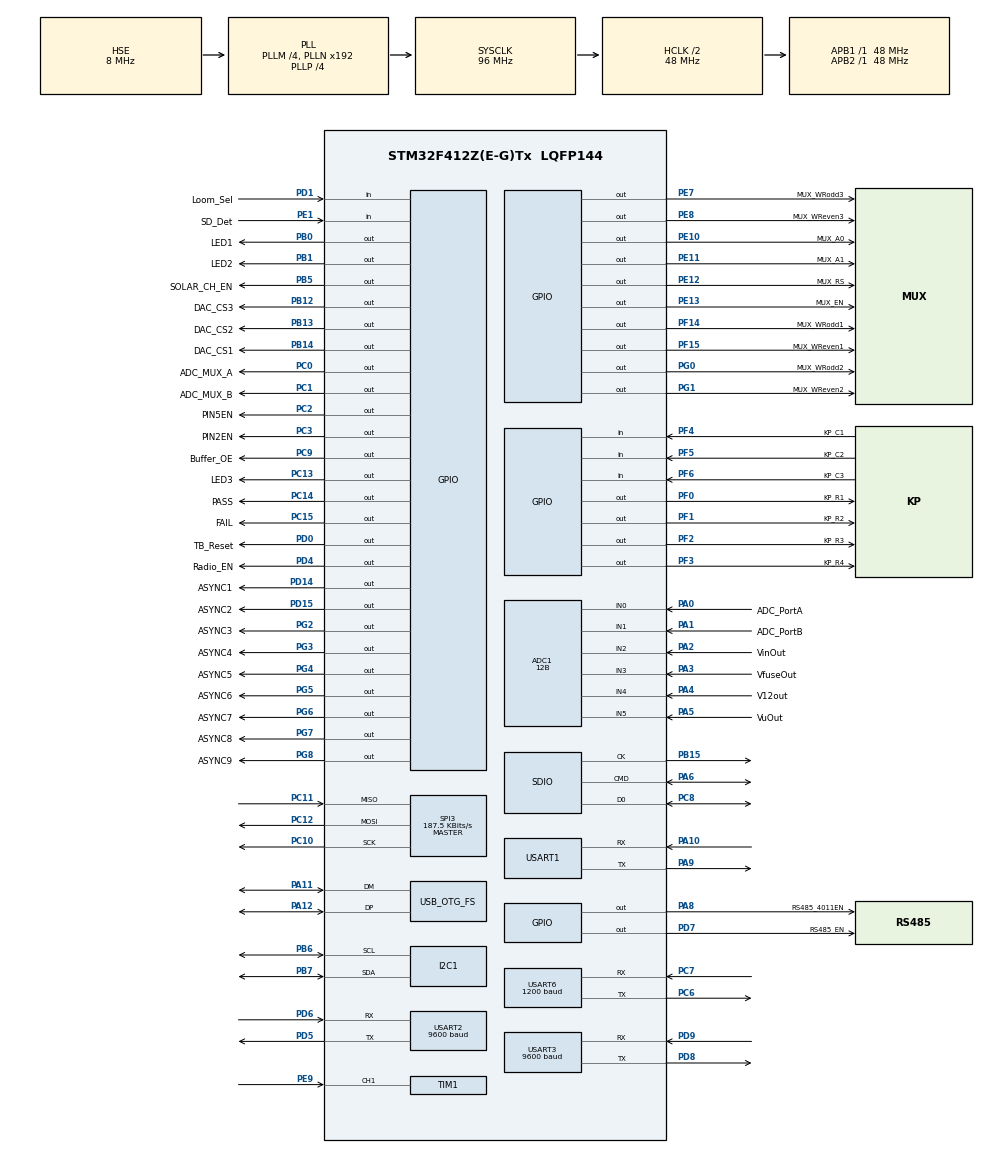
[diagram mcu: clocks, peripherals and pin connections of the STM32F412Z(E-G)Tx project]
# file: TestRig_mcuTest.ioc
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ADC1.Channel-0\#ChannelRegularConversion=ADC_CHANNEL_0
ADC1.ClockPrescaler=ADC_CLOCK_SYNC_PCLK_DIV2
ADC1.ContinuousConvMode=ENABLE
ADC1.DMAContinuousRequestsForConfigFile-ADC_Settings=LIMITED
ADC1.EOCSelection=ADC_EOC_SINGLE_CONV
ADC1.InjNumberOfConversion=0
ADC1.NbrOfConversion=1
ADC1.NbrOfConversionFlag=1
ADC1.Rank-0\#ChannelRegularConversion=1
ADC1.Resolution=ADC_RESOLUTION_12B
ADC1.SamplingTime-0\#ChannelRegularConversion=ADC_SAMPLETIME_3CYCLES
ADC1.ScanConvMode=ENABLE
ADC1.master=1
FATFS._FS_RPATH=1
FATFS._USE_CHMOD=0
FATFS._USE_FIND=1
FATFS._USE_LFN=1
Mcu.Family=STM32F4
Mcu.Name=STM32F412Z(E-G)Tx
Mcu.Package=LQFP144
NVIC.OTG_FS_IRQn=true\:0\:0\:false\:false\:true\:false\:true
NVIC.PriorityGroup=NVIC_PRIORITYGROUP_4
NVIC.TIM1_TRG_COM_TIM11_IRQn=true\:0\:0\:false\:false\:true\:true\:true
NVIC.TIM1_UP_TIM10_IRQn=true\:0\:0\:false\:false\:true\:true\:true
NVIC.TIM6_IRQn=true\:0\:0\:false\:false\:true\:true\:true
NVIC.TIM7_IRQn=true\:0\:0\:false\:false\:true\:true\:true
NVIC.TIM8_TRG_COM_TIM14_IRQn=true\:0\:0\:false\:false\:true\:true\:true
NVIC.USART2_IRQn=true\:0\:0\:false\:false\:true\:true\:true
NVIC.USART3_IRQn=true\:0\:0\:false\:false\:true\:true\:true
NVIC.USART6_IRQn=true\:0\:0\:false\:false\:true\:true\:true
PA0.GPIO_Label=ADC_PortA
PA0.Signal=ADCx_IN0
PA1.GPIO_Label=ADC_PortB
PA1.Signal=ADCx_IN1
PA10.Mode=Asynchronous
PA10.Signal=USART1_RX
PA11.Mode=Device_Only
PA11.Signal=USB_OTG_FS_DM
PA12.Mode=Device_Only
PA12.Signal=USB_OTG_FS_DP
PA13.Mode=Trace_Asynchronous_SW
PA13.Signal=SYS_JTMS-SWDIO
PA14.Mode=Trace_Asynchronous_SW
PA14.Signal=SYS_JTCK-SWCLK
PA2.GPIO_Label=VinOut
PA2.Signal=ADCx_IN2
PA3.GPIO_Label=VfuseOut
PA3.Signal=ADCx_IN3
PA4.GPIO_Label=V12out
PA4.Signal=ADCx_IN4
PA5.GPIO_Label=VuOut
PA5.Signal=ADCx_IN5
PA6.Mode=SD_1_bit
PA6.Signal=SDIO_CMD
PA8.GPIO_Label=RS485_4011EN
PA8.Signal=GPIO_Output
PA9.Mode=Asynchronous
PA9.Signal=USART1_TX
PB0.GPIO_Label=LED1
PB0.Signal=GPIO_Output
PB1.GPIO_Label=LED2
PB1.GPIO_Speed=GPIO_SPEED_FREQ_HIGH
PB1.Signal=GPIO_Output
PB12.GPIO_Label=DAC_CS3
PB12.Signal=GPIO_Output
PB13.GPIO_Label=DAC_CS2
PB13.Signal=GPIO_Output
PB14.GPIO_Label=DAC_CS1
PB14.Signal=GPIO_Output
PB15.Mode=SD_1_bit
PB15.Signal=SDIO_CK
PB3.Mode=Trace_Asynchronous_SW
PB3.Signal=SYS_JTDO-SWO
PB5.GPIO_Label=SOLAR_CH_EN
PB5.Signal=GPIO_Output
PB6.Mode=I2C
PB6.Signal=I2C1_SCL
PB7.Mode=I2C
PB7.Signal=I2C1_SDA
PC0.GPIO_Label=ADC_MUX_A
PC0.Signal=GPIO_Output
PC1.GPIO_Label=ADC_MUX_B
PC1.Signal=GPIO_Output
PC10.Mode=Full_Duplex_Master
PC10.Signal=SPI3_SCK
PC11.Mode=Full_Duplex_Master
PC11.Signal=SPI3_MISO
PC12.Mode=Full_Duplex_Master
PC12.Signal=SPI3_MOSI
PC13.GPIO_Label=LED3
PC13.Signal=GPIO_Output
PC14-OSC32_IN.GPIO_Label=PASS
PC14-OSC32_IN.Signal=GPIO_Output
PC15-OSC32_OUT.GPIO_Label=FAIL
PC15-OSC32_OUT.Signal=GPIO_Output
PC2.GPIO_Label=PIN5EN
PC2.Signal=GPIO_Output
PC3.GPIO_Label=PIN2EN
PC3.Signal=GPIO_Output
PC6.Mode=Asynchronous
PC6.Signal=USART6_TX
PC7.Mode=Asynchronous
PC7.Signal=USART6_RX
PC8.Mode=SD_1_bit
PC8.Signal=SDIO_D0
PC9.GPIO_Label=Buffer_OE
PC9.Signal=GPIO_Output
PD0.GPIO_Label=TB_Reset
PD0.GPIO_PuPd=GPIO_NOPULL
PD0.Signal=GPIO_Output
PD1.GPIO_Label=Loom_Sel
PD1.GPIO_PuPd=GPIO_PULLUP
PD1.Signal=GPIO_Input
PD14.GPIO_Label=ASYNC1
PD14.GPIO_Speed=GPIO_SPEED_FREQ_VERY_HIGH
PD14.Signal=GPIO_Output
PD15.GPIO_Label=ASYNC2
PD15.GPIO_Speed=GPIO_SPEED_FREQ_VERY_HIGH
PD15.Signal=GPIO_Output
PD4.GPIO_Label=Radio_EN
PD4.Signal=GPIO_Output
PD5.Mode=Asynchronous
PD5.Signal=USART2_TX
PD6.Mode=Asynchronous
PD6.Signal=USART2_RX
PD7.GPIO_Label=RS485_EN
PD7.Signal=GPIO_Output
PD8.Mode=Asynchronous
PD8.Signal=USART3_TX
PD9.Mode=Asynchronous
PD9.Signal=USART3_RX
PE1.GPIO_Label=SD_Det
PE1.Signal=GPIO_Input
PE10.GPIO_Label=MUX_A0
PE10.Signal=GPIO_Output
PE11.GPIO_Label=MUX_A1
PE11.Signal=GPIO_Output
PE12.GPIO_Label=MUX_RS
PE12.PinState=GPIO_PIN_SET
PE12.Signal=GPIO_Output
PE13.GPIO_Label=MUX_EN
PE13.Signal=GPIO_Output
PE7.GPIO_Label=MUX_WRodd3
PE7.PinState=GPIO_PIN_SET
PE7.Signal=GPIO_Output
PE8.GPIO_Label=MUX_WReven3
PE8.PinState=GPIO_PIN_SET
PE8.Signal=GPIO_Output
PE9.Signal=S_TIM1_CH1
PF0.GPIO_Label=KP_R1
PF0.Signal=GPIO_Output
PF1.GPIO_Label=KP_R2
PF1.Signal=GPIO_Output
PF14.GPIO_Label=MUX_WRodd1
PF14.GPIO_PuPd=GPIO_PULLUP
PF14.PinState=GPIO_PIN_SET
PF14.Signal=GPIO_Output
PF15.GPIO_Label=MUX_WReven1
PF15.GPIO_PuPd=GPIO_PULLUP
PF15.PinState=GPIO_PIN_SET
PF15.Signal=GPIO_Output
PF2.GPIO_Label=KP_R3
PF2.Signal=GPIO_Output
PF3.GPIO_Label=KP_R4
PF3.Signal=GPIO_Output
PF4.GPIO_Label=KP_C1
PF4.GPIO_PuPd=GPIO_PULLUP
PF4.Signal=GPIO_Input
PF5.GPIO_Label=KP_C2
PF5.GPIO_PuPd=GPIO_PULLUP
PF5.Signal=GPIO_Input
PF6.GPIO_Label=KP_C3
PF6.GPIO_PuPd=GPIO_PULLUP
PF6.Signal=GPIO_Input
PG0.GPIO_Label=MUX_WRodd2
PG0.PinState=GPIO_PIN_SET
PG0.Signal=GPIO_Output
PG1.GPIO_Label=MUX_WReven2
PG1.PinState=GPIO_PIN_SET
PG1.Signal=GPIO_Output
PG2.GPIO_Label=ASYNC3
PG2.GPIO_Speed=GPIO_SPEED_FREQ_VERY_HIGH
PG2.PinState=GPIO_PIN_RESET
PG2.Signal=GPIO_Output
PG3.GPIO_Label=ASYNC4
PG3.GPIO_Speed=GPIO_SPEED_FREQ_VERY_HIGH
PG3.Signal=GPIO_Output
PG4.GPIO_Label=ASYNC5
PG4.Signal=GPIO_Output
PG5.GPIO_Label=ASYNC6
PG5.Signal=GPIO_Output
PG6.GPIO_Label=ASYNC7
PG6.Signal=GPIO_Output
PG7.GPIO_Label=ASYNC8
PG7.Signal=GPIO_Output
PG8.GPIO_Label=ASYNC9
PG8.Signal=GPIO_Output
PH0\ -\ OSC_IN.Mode=HSE-External-Oscillator
PH0\ -\ OSC_IN.Signal=RCC_OSC_IN
PH1\ -\ OSC_OUT.Mode=HSE-External-Oscillator
PH1\ -\ OSC_OUT.Signal=RCC_OSC_OUT
ProjectManager.HeapSize=0x200
ProjectManager.StackSize=0x400
ProjectManager.TargetToolchain=STM32CubeIDE
RCC.AHBCLKDivider=RCC_SYSCLK_DIV2
RCC.AHBFreq_Value=48000000
RCC.APB1Freq_Value=48000000
RCC.APB1TimFreq_Value=48000000
RCC.APB2Freq_Value=48000000
RCC.APB2TimFreq_Value=48000000
RCC.CortexFreq_Value=48000000
RCC.HCLKFreq_Value=48000000
RCC.HSE_VALUE=8000000
RCC.PLLM=4
RCC.PLLP=RCC_PLLP_DIV4
RCC.PLLQ=8
RCC.PLLSourceVirtual=RCC_PLLSOURCE_HSE
RCC.SYSCLKFreq_VALUE=96000000
RCC.SYSCLKSource=RCC_SYSCLKSOURCE_PLLCLK
RCC.USBFreq_Value=48000000
RCC.VCOOutputFreq_Value=384000000
SDIO.ClockDiv=2
SDIO.HardwareFlowControl=SDIO_HARDWARE_FLOW_CONTROL_ENABLE
SH.ADCx_IN0.0=ADC1_IN0,IN0
SH.ADCx_IN1.0=ADC1_IN1,IN1
SH.ADCx_IN2.0=ADC1_IN2,IN2
SH.ADCx_IN3.0=ADC1_IN3,IN3
SH.ADCx_IN4.0=ADC1_IN4,IN4
SH.ADCx_IN5.0=ADC1_IN5,IN5
SH.S_TIM1_CH1.0=TIM1_CH1,Input_Capture1_from_TI1
SPI3.BaudRatePrescaler=SPI_BAUDRATEPRESCALER_256
SPI3.CalculateBaudRate=187.5 KBits/s
SPI3.DataSize=SPI_DATASIZE_8BIT
SPI3.Direction=SPI_DIRECTION_2LINES
SPI3.Mode=SPI_MODE_MASTER
SPI3.VirtualType=VM_MASTER
TIM1.Channel-Input_Capture1_from_TI1=TIM_CHANNEL_1
TIM10.AutoReloadPreload=TIM_AUTORELOAD_PRELOAD_ENABLE
TIM10.Period=99
TIM10.Prescaler=239
TIM11.AutoReloadPreload=TIM_AUTORELOAD_PRELOAD_ENABLE
TIM11.Period=47
TIM11.Prescaler=999
TIM13.AutoReloadPreload=TIM_AUTORELOAD_PRELOAD_ENABLE
TIM13.Period=1
TIM13.Prescaler=23
TIM14.AutoReloadPreload=TIM_AUTORELOAD_PRELOAD_ENABLE
TIM14.Period=99
TIM14.Prescaler=239
TIM6.AutoReloadPreload=TIM_AUTORELOAD_PRELOAD_ENABLE
TIM6.Period=479
TIM6.Prescaler=999
TIM7.Period=47
TIM7.Prescaler=999
USART1.VirtualMode=VM_ASYNC
USART2.BaudRate=9600
USART2.VirtualMode=VM_ASYNC
USART3.BaudRate=9600
USART3.VirtualMode=VM_ASYNC
USART6.BaudRate=1200
USART6.Parity=PARITY_EVEN
USART6.VirtualMode=VM_ASYNC
USB_DEVICE.CLASS_NAME_FS=CDC
USB_DEVICE.MANUFACTURER_STRING=MAIT INDUSTRIES
USB_DEVICE.PRODUCT_STRING_CDC_FS=TESTRIG
USB_DEVICE.VirtualMode=Cdc
USB_DEVICE.VirtualModeFS=Cdc_FS
USB_OTG_FS.VirtualMode=Device_Only
VP_FATFS_VS_SDIO.Mode=SDIO
VP_RNG_VS_RNG.Mode=RNG_Activate
VP_TIM10_VS_ClockSourceINT.Mode=Enable_Timer
VP_TIM11_VS_ClockSourceINT.Mode=Enable_Timer
VP_TIM13_VS_ClockSourceINT.Mode=Enable_Timer
VP_TIM14_VS_ClockSourceINT.Mode=Enable_Timer
VP_TIM6_VS_ClockSourceINT.Mode=Enable_Timer
VP_TIM7_VS_ClockSourceINT.Mode=Enable_Timer
VP_USB_DEVICE_VS_USB_DEVICE_CDC_FS.Mode=CDC_FS
board=custom

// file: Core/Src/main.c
/* USER CODE BEGIN Header */
/**
 ******************************************************************************
 * @file           : main.c
 * @brief          : Main program body
 ******************************************************************************
 * @attention
 *
 * <h2><center>&copy; Copyright (c) 2021 STMicroelectronics.
 * All rights reserved.</center></h2>
 *
 * This software component is licensed by ST under BSD 3-Clause license,
 * the "License"; You may not use this file except in compliance with the
 * License. You may obtain a copy of the License at:
 *                        opensource.org/licenses/BSD-3-Clause
 *
 ******************************************************************************
 */
/* USER CODE END Header */
#include "main.h"
#include "fatfs.h"
#include "usb_device.h"

/* USER CODE BEGIN Includes */
#include "ADC_Variables.h"
#include "ADC.h"
#include "Board_Config.h"
#include "Calibration.h"
#include "DAC_Variables.h"
#include "EEPROM.h"
#include "File_Handling.h"
#include "Global_Variables.h"
#include "Init.h"
#include "LCD.h"
#include "Programming.h"
#include "ScanLoom.h"
#include "SDcard.h"
#include "SetVsMeasured.h"
#include "StateMachine.h"
#include "Test.h"
#include "UART_Routine.h"
#include "usbd_cdc_if.h"
/* USER CODE END Includes */

/* USER CODE BEGIN PTD */
extern void reset_ALL_DAC(void);
extern void Async_Init(void);
extern void delay_us(int);
/* USER CODE END PTD */

ADC_HandleTypeDef hadc1;

I2C_HandleTypeDef hi2c1;

RNG_HandleTypeDef hrng;

SD_HandleTypeDef hsd;

SPI_HandleTypeDef hspi3;

TIM_HandleTypeDef htim1;
TIM_HandleTypeDef htim6;
TIM_HandleTypeDef htim7;
TIM_HandleTypeDef htim10;
TIM_HandleTypeDef htim11;
TIM_HandleTypeDef htim13;
TIM_HandleTypeDef htim14;

UART_HandleTypeDef huart1;
UART_HandleTypeDef huart2;
UART_HandleTypeDef huart3;
UART_HandleTypeDef huart6;

void SystemClock_Config(void);
static void MX_GPIO_Init(void);
static void MX_ADC1_Init(void);
static void MX_I2C1_Init(void);
static void MX_SDIO_SD_Init(void);
static void MX_SPI3_Init(void);
static void MX_TIM6_Init(void);
static void MX_TIM7_Init(void);
static void MX_TIM13_Init(void);
static void MX_TIM14_Init(void);
static void MX_USART2_UART_Init(void);
static void MX_USART3_UART_Init(void);
static void MX_USART6_UART_Init(void);
static void MX_TIM10_Init(void);
static void MX_USART1_UART_Init(void);
static void MX_TIM11_Init(void);
static void MX_RNG_Init(void);
static void MX_TIM1_Init(void);
/* USER CODE BEGIN PFP */
uint32 read_serial(void);
void read_correctionFactors(void);
void write_correctionFactors(void);
void LCD_init(void);
/* USER CODE END PFP */

int main(void)
{

  /* MCU Configuration--------------------------------------------------------*/

  /* Reset of all peripherals, Initializes the Flash interface and the Systick. */

	HAL_Init();

  /* USER CODE BEGIN Init */

  /* USER CO DE END Init */

  /* Configure the system clock */
  SystemClock_Config();

  /* Initialize all configured peripherals */
  MX_GPIO_Init();
  MX_ADC1_Init();
  MX_I2C1_Init();
  MX_SDIO_SD_Init();
  MX_SPI3_Init();
  MX_TIM6_Init();
  MX_TIM7_Init();
  MX_TIM13_Init();
  MX_TIM14_Init();
  MX_USART2_UART_Init();
  MX_USART3_UART_Init();
  MX_USART6_UART_Init();
  MX_FATFS_Init();
  MX_USB_DEVICE_Init();
  MX_TIM10_Init();
  MX_USART1_UART_Init();
  MX_TIM11_Init();
  MX_RNG_Init();
  MX_TIM1_Init();
  /* USER CODE BEGIN 2 */					// TODO: Implement watchdog timer to ensure the system resets if the system gets halted
//  HAL_Delay(2000);
	HAL_I2C_Init(&hi2c1);
	LCD_init();
	ChangeCharacterSet('A');				// Character set A for Progress Bar
	PrintTestRigFirmwareVersion();			// Print the current firmware version on the LCD screen

	TestRig_Init();
	DebounceArrayInit();					// Initialize the async debounce functionality array
	populateSetSampleVoltages();
	ProcessState = psInitalisation;
	CurrentState = csCheckLoom;				// Determine what loom is connected first
	CheckLoomTimer = 0;

	ConfigInit();							// Initialize test codes
	read_correctionFactors();				// Read the calibration correction factors
	SDcard.fresult = SDInit(&SDcard, "");	// Initialize SDcard
  /* USER CODE END 2 */

  /* Infinite loop */
	while (1) {
    /* USER CODE BEGIN 3 */
//=========================================================================================================//
		/*
		 * When a process is complete, via either a response from the target board or a timeout the system
		 * will return here to continue with the testing procedure, resetting the current state and resetting
		 * the process state to waiting.
		 */

		if ( (CurrentState != csProgramming) && (CurrentState != csLatchTest) && (CurrentState != csCalibrating) && (CheckLoomTimer == 0) )
			ScanLoom(&LoomState);	// Scan loom each time through the state machine to determine when a loom is removed mid process

		switch (CurrentState) {	// Main statemachine for the system, handles change of state and most activity (excluding quiting & check loom functionality)
		case csCheckLoom:
			handleCheckLoom(&BoardConnected, &ProcessState);
			break;
		case csIDLE:
			handleIdle(&BoardConnected, &ProcessState);
			break;
		case csSerialNumberEntry:
			handleSerialNumberEntry(&BoardConnected, &ProcessState);
			break;
		case csSolarCharger:
			handleSolarCharger(&BoardConnected, &ProcessState);
			break;
		case csInputVoltage:
			handleInputVoltage(&BoardConnected, &ProcessState);
			break;
		case csInitialising:
			handleInitialising(&BoardConnected, &ProcessState);
			break;
		case csProgramming:
			handleProgramming(&BoardConnected, &ProcessState);
			break;
		case csCalibrating:
			handleCalibrating(&BoardConnected, &ProcessState);
			break;
		case csInterogating: //0x09 & 0x35
			handleInterogating(&BoardConnected, &ProcessState);
			break;
		case csOutputTest:
			handleOutputTest(&BoardConnected, &ProcessState);
			break;
		case csLatchTest:
			handleLatchTest(&BoardConnected, &ProcessState);
			break;
		case csAsyncTest:
			handleAsyncTest(&BoardConnected, &ProcessState);
			break;
		case csConfiguring: // 0x57
			handleConfiguring(&BoardConnected, &ProcessState);
			break;
		case csSampling: // 0x1B
			handleSampling(&BoardConnected, &ProcessState);
			break;
		case csUploading: // 0x19
			handleUploading(&BoardConnected, &ProcessState);
			break;
		case csSortResults:
			handleSortResults(&BoardConnected, &ProcessState);
			break;
		case csSerialise:
			handleSerialise(&BoardConnected, &ProcessState);
			break;

		}
//=========================================================================================================//

		//=========================================================================================================//
		// Quit
		if (KP[star].Pressed && QuitEnabled) {									// Check if the back/exit button is pressed
			KP[star].Pressed = false;
			LCD_Clear();
			TestRig_Init();										// Clear LCD screen and return system to home defaults
			if (CurrentState == csProgramming) {
				HAL_GPIO_WritePin(PIN2EN_GPIO_Port, PIN2EN_Pin, GPIO_PIN_RESET);
				HAL_GPIO_WritePin(PIN5EN_GPIO_Port, PIN5EN_Pin, GPIO_PIN_RESET);
				TargetBoardParamInit(0);
				CurrentState = csSerialNumberEntry;
			} else {
				CurrentState = csCheckLoom;
				TargetBoardParamInit(true);							// Fully erase BoardConnected struct and associated memory
			}
			ProcessState = psInitalisation;
		}
//=========================================================================================================//
	}
//=========================================================================================================//

//=========================================================================================================//
  /* USER CODE END 3 */
}

void SystemClock_Config(void)
{
  RCC_OscInitTypeDef RCC_OscInitStruct = {0};
  RCC_ClkInitTypeDef RCC_ClkInitStruct = {0};
  RCC_PeriphCLKInitTypeDef PeriphClkInitStruct = {0};

  /** Configure the main internal regulator output voltage
  */
  __HAL_RCC_PWR_CLK_ENABLE();
  __HAL_PWR_VOLTAGESCALING_CONFIG(PWR_REGULATOR_VOLTAGE_SCALE1);
  /** Initializes the RCC Oscillators according to the specified parameters
  * in the RCC_OscInitTypeDef structure.
  */
  RCC_OscInitStruct.OscillatorType = RCC_OSCILLATORTYPE_HSE;
  RCC_OscInitStruct.HSEState = RCC_HSE_ON;
  RCC_OscInitStruct.PLL.PLLState = RCC_PLL_ON;
  RCC_OscInitStruct.PLL.PLLSource = RCC_PLLSOURCE_HSE;
  RCC_OscInitStruct.PLL.PLLM = 4;
  RCC_OscInitStruct.PLL.PLLN = 192;
  RCC_OscInitStruct.PLL.PLLP = RCC_PLLP_DIV4;
  RCC_OscInitStruct.PLL.PLLQ = 8;
  RCC_OscInitStruct.PLL.PLLR = 2;
  if (HAL_RCC_OscConfig(&RCC_OscInitStruct) != HAL_OK)
  {
    Error_Handler();
  }
  /** Initializes the CPU, AHB and APB buses clocks
  */
  RCC_ClkInitStruct.ClockType = RCC_CLOCKTYPE_HCLK|RCC_CLOCKTYPE_SYSCLK
                              |RCC_CLOCKTYPE_PCLK1|RCC_CLOCKTYPE_PCLK2;
  RCC_ClkInitStruct.SYSCLKSource = RCC_SYSCLKSOURCE_PLLCLK;
  RCC_ClkInitStruct.AHBCLKDivider = RCC_SYSCLK_DIV2;
  RCC_ClkInitStruct.APB1CLKDivider = RCC_HCLK_DIV1;
  RCC_ClkInitStruct.APB2CLKDivider = RCC_HCLK_DIV1;

  if (HAL_RCC_ClockConfig(&RCC_ClkInitStruct, FLASH_LATENCY_1) != HAL_OK)
  {
    Error_Handler();
  }
  PeriphClkInitStruct.PeriphClockSelection = RCC_PERIPHCLK_SDIO|RCC_PERIPHCLK_CLK48;
  PeriphClkInitStruct.Clk48ClockSelection = RCC_CLK48CLKSOURCE_PLLQ;
  PeriphClkInitStruct.SdioClockSelection = RCC_SDIOCLKSOURCE_CLK48;
  if (HAL_RCCEx_PeriphCLKConfig(&PeriphClkInitStruct) != HAL_OK)
  {
    Error_Handler();
  }
}

static void MX_ADC1_Init(void)
{

  ADC_ChannelConfTypeDef sConfig = {0};

  /** Configure the global features of the ADC (Clock, Resolution, Data Alignment and number of conversion)
  */
  hadc1.Instance = ADC1;
  hadc1.Init.ClockPrescaler = ADC_CLOCK_SYNC_PCLK_DIV2;
  hadc1.Init.Resolution = ADC_RESOLUTION_12B;
  hadc1.Init.ScanConvMode = ENABLE;
  hadc1.Init.ContinuousConvMode = ENABLE;
  hadc1.Init.DiscontinuousConvMode = DISABLE;
  hadc1.Init.ExternalTrigConvEdge = ADC_EXTERNALTRIGCONVEDGE_NONE;
  hadc1.Init.ExternalTrigConv = ADC_SOFTWARE_START;
  hadc1.Init.DataAlign = ADC_DATAALIGN_RIGHT;
  hadc1.Init.NbrOfConversion = 1;
  hadc1.Init.DMAContinuousRequests = DISABLE;
  hadc1.Init.EOCSelection = ADC_EOC_SINGLE_CONV;
  if (HAL_ADC_Init(&hadc1) != HAL_OK)
  {
    Error_Handler();
  }
  /** Configure for the selected ADC regular channel its corresponding rank in the sequencer and its sample time.
  */
  sConfig.Channel = ADC_CHANNEL_0;
  sConfig.Rank = 1;
  sConfig.SamplingTime = ADC_SAMPLETIME_3CYCLES;
  if (HAL_ADC_ConfigChannel(&hadc1, &sConfig) != HAL_OK)
  {
    Error_Handler();
  }

}

static void MX_I2C1_Init(void)
{

  hi2c1.Instance = I2C1;
  hi2c1.Init.ClockSpeed = 100000;
  hi2c1.Init.DutyCycle = I2C_DUTYCYCLE_2;
  hi2c1.Init.OwnAddress1 = 0;
  hi2c1.Init.AddressingMode = I2C_ADDRESSINGMODE_7BIT;
  hi2c1.Init.DualAddressMode = I2C_DUALADDRESS_DISABLE;
  hi2c1.Init.OwnAddress2 = 0;
  hi2c1.Init.GeneralCallMode = I2C_GENERALCALL_DISABLE;
  hi2c1.Init.NoStretchMode = I2C_NOSTRETCH_DISABLE;
  if (HAL_I2C_Init(&hi2c1) != HAL_OK)
  {
    Error_Handler();
  }

}

static void MX_RNG_Init(void)
{

  hrng.Instance = RNG;
  if (HAL_RNG_Init(&hrng) != HAL_OK)
  {
    Error_Handler();
  }

}

static void MX_SDIO_SD_Init(void)
{

  hsd.Instance = SDIO;
  hsd.Init.ClockEdge = SDIO_CLOCK_EDGE_RISING;
  hsd.Init.ClockBypass = SDIO_CLOCK_BYPASS_DISABLE;
  hsd.Init.ClockPowerSave = SDIO_CLOCK_POWER_SAVE_DISABLE;
  hsd.Init.BusWide = SDIO_BUS_WIDE_1B;
  hsd.Init.HardwareFlowControl = SDIO_HARDWARE_FLOW_CONTROL_ENABLE;
  hsd.Init.ClockDiv = 2;

}

static void MX_SPI3_Init(void)
{

  /* SPI3 parameter configuration*/
  hspi3.Instance = SPI3;
  hspi3.Init.Mode = SPI_MODE_MASTER;
  hspi3.Init.Direction = SPI_DIRECTION_2LINES;
  hspi3.Init.DataSize = SPI_DATASIZE_8BIT;
  hspi3.Init.CLKPolarity = SPI_POLARITY_LOW;
  hspi3.Init.CLKPhase = SPI_PHASE_1EDGE;
  hspi3.Init.NSS = SPI_NSS_SOFT;
  hspi3.Init.BaudRatePrescaler = SPI_BAUDRATEPRESCALER_256;
  hspi3.Init.FirstBit = SPI_FIRSTBIT_MSB;
  hspi3.Init.TIMode = SPI_TIMODE_DISABLE;
  hspi3.Init.CRCCalculation = SPI_CRCCALCULATION_DISABLE;
  hspi3.Init.CRCPolynomial = 10;
  if (HAL_SPI_Init(&hspi3) != HAL_OK)
  {
    Error_Handler();
  }

}

static void MX_TIM1_Init(void)
{

  TIM_MasterConfigTypeDef sMasterConfig = {0};
  TIM_IC_InitTypeDef sConfigIC = {0};

  htim1.Instance = TIM1;
  htim1.Init.Prescaler = 0;
  htim1.Init.CounterMode = TIM_COUNTERMODE_UP;
  htim1.Init.Period = 65535;
  htim1.Init.ClockDivision = TIM_CLOCKDIVISION_DIV1;
  htim1.Init.RepetitionCounter = 0;
  htim1.Init.AutoReloadPreload = TIM_AUTORELOAD_PRELOAD_DISABLE;
  if (HAL_TIM_IC_Init(&htim1) != HAL_OK)
  {
    Error_Handler();
  }
  sMasterConfig.MasterOutputTrigger = TIM_TRGO_RESET;
  sMasterConfig.MasterSlaveMode = TIM_MASTERSLAVEMODE_DISABLE;
  if (HAL_TIMEx_MasterConfigSynchronization(&htim1, &sMasterConfig) != HAL_OK)
  {
    Error_Handler();
  }
  sConfigIC.ICPolarity = TIM_INPUTCHANNELPOLARITY_RISING;
  sConfigIC.ICSelection = TIM_ICSELECTION_DIRECTTI;
  sConfigIC.ICPrescaler = TIM_ICPSC_DIV1;
  sConfigIC.ICFilter = 0;
  if (HAL_TIM_IC_ConfigChannel(&htim1, &sConfigIC, TIM_CHANNEL_1) != HAL_OK)
  {
    Error_Handler();
  }

}

static void MX_TIM6_Init(void)
{

  TIM_MasterConfigTypeDef sMasterConfig = {0};

  htim6.Instance = TIM6;
  htim6.Init.Prescaler = 999;
  htim6.Init.CounterMode = TIM_COUNTERMODE_UP;
  htim6.Init.Period = 479;
  htim6.Init.AutoReloadPreload = TIM_AUTORELOAD_PRELOAD_ENABLE;
  if (HAL_TIM_Base_Init(&htim6) != HAL_OK)
  {
    Error_Handler();
  }
  sMasterConfig.MasterOutputTrigger = TIM_TRGO_RESET;
  sMasterConfig.MasterSlaveMode = TIM_MASTERSLAVEMODE_DISABLE;
  if (HAL_TIMEx_MasterConfigSynchronization(&htim6, &sMasterConfig) != HAL_OK)
  {
    Error_Handler();
  }

}

static void MX_TIM7_Init(void)
{

  htim7.Instance = TIM7;
  htim7.Init.Prescaler = 999;
  htim7.Init.CounterMode = TIM_COUNTERMODE_UP;
  htim7.Init.Period = 47;
  htim7.Init.AutoReloadPreload = TIM_AUTORELOAD_PRELOAD_DISABLE;
  if (HAL_TIM_Base_Init(&htim7) != HAL_OK)
  {
    Error_Handler();
  }

}

static void MX_TIM10_Init(void)
{

  htim10.Instance = TIM10;
  htim10.Init.Prescaler = 239;
  htim10.Init.CounterMode = TIM_COUNTERMODE_UP;
  htim10.Init.Period = 99;
  htim10.Init.ClockDivision = TIM_CLOCKDIVISION_DIV1;
  htim10.Init.AutoReloadPreload = TIM_AUTORELOAD_PRELOAD_ENABLE;
  if (HAL_TIM_Base_Init(&htim10) != HAL_OK)
  {
    Error_Handler();
  }

}

static void MX_TIM11_Init(void)
{

  htim11.Instance = TIM11;
  htim11.Init.Prescaler = 999;
  htim11.Init.CounterMode = TIM_COUNTERMODE_UP;
  htim11.Init.Period = 47;
  htim11.Init.ClockDivision = TIM_CLOCKDIVISION_DIV1;
  htim11.Init.AutoReloadPreload = TIM_AUTORELOAD_PRELOAD_ENABLE;
  if (HAL_TIM_Base_Init(&htim11) != HAL_OK)
  {
    Error_Handler();
  }

}

static void MX_TIM13_Init(void)
{

  htim13.Instance = TIM13;
  htim13.Init.Prescaler = 23;
  htim13.Init.CounterMode = TIM_COUNTERMODE_UP;
  htim13.Init.Period = 1;
  htim13.Init.ClockDivision = TIM_CLOCKDIVISION_DIV1;
  htim13.Init.AutoReloadPreload = TIM_AUTORELOAD_PRELOAD_ENABLE;
  if (HAL_TIM_Base_Init(&htim13) != HAL_OK)
  {
    Error_Handler();
  }

}

static void MX_TIM14_Init(void)
{

  htim14.Instance = TIM14;
  htim14.Init.Prescaler = 239;
  htim14.Init.CounterMode = TIM_COUNTERMODE_UP;
  htim14.Init.Period = 99;
  htim14.Init.ClockDivision = TIM_CLOCKDIVISION_DIV1;
  htim14.Init.AutoReloadPreload = TIM_AUTORELOAD_PRELOAD_ENABLE;
  if (HAL_TIM_Base_Init(&htim14) != HAL_OK)
  {
    Error_Handler();
  }

}

static void MX_USART1_UART_Init(void)
{

  huart1.Instance = USART1;
  huart1.Init.BaudRate = 115200;
  huart1.Init.WordLength = UART_WORDLENGTH_8B;
  huart1.Init.StopBits = UART_STOPBITS_1;
  huart1.Init.Parity = UART_PARITY_NONE;
  huart1.Init.Mode = UART_MODE_TX_RX;
  huart1.Init.HwFlowCtl = UART_HWCONTROL_NONE;
  huart1.Init.OverSampling = UART_OVERSAMPLING_16;
  if (HAL_UART_Init(&huart1) != HAL_OK)
  {
    Error_Handler();
  }

}

static void MX_USART2_UART_Init(void)
{

  huart2.Instance = USART2;
  huart2.Init.BaudRate = 9600;
  huart2.Init.WordLength = UART_WORDLENGTH_8B;
  huart2.Init.StopBits = UART_STOPBITS_1;
  huart2.Init.Parity = UART_PARITY_NONE;
  huart2.Init.Mode = UART_MODE_TX_RX;
  huart2.Init.HwFlowCtl = UART_HWCONTROL_NONE;
  huart2.Init.OverSampling = UART_OVERSAMPLING_16;
  if (HAL_UART_Init(&huart2) != HAL_OK)
  {
    Error_Handler();
  }

}

static void MX_USART3_UART_Init(void)
{

  huart3.Instance = USART3;
  huart3.Init.BaudRate = 9600;
  huart3.Init.WordLength = UART_WORDLENGTH_8B;
  huart3.Init.StopBits = UART_STOPBITS_1;
  huart3.Init.Parity = UART_PARITY_NONE;
  huart3.Init.Mode = UART_MODE_TX_RX;
  huart3.Init.HwFlowCtl = UART_HWCONTROL_NONE;
  huart3.Init.OverSampling = UART_OVERSAMPLING_16;
  if (HAL_UART_Init(&huart3) != HAL_OK)
  {
    Error_Handler();
  }

}

static void MX_USART6_UART_Init(void)
{

  huart6.Instance = USART6;
  huart6.Init.BaudRate = 1200;
  huart6.Init.WordLength = UART_WORDLENGTH_8B;
  huart6.Init.StopBits = UART_STOPBITS_1;
  huart6.Init.Parity = UART_PARITY_EVEN;
  huart6.Init.Mode = UART_MODE_TX_RX;
  huart6.Init.HwFlowCtl = UART_HWCONTROL_NONE;
  huart6.Init.OverSampling = UART_OVERSAMPLING_16;
  if (HAL_UART_Init(&huart6) != HAL_OK)
  {
    Error_Handler();
  }

}

static void MX_GPIO_Init(void)
{
  GPIO_InitTypeDef GPIO_InitStruct = {0};

  /* GPIO Ports Clock Enable */
  __HAL_RCC_GPIOC_CLK_ENABLE();
  __HAL_RCC_GPIOF_CLK_ENABLE();
  __HAL_RCC_GPIOH_CLK_ENABLE();
  __HAL_RCC_GPIOA_CLK_ENABLE();
  __HAL_RCC_GPIOB_CLK_ENABLE();
  __HAL_RCC_GPIOG_CLK_ENABLE();
  __HAL_RCC_GPIOE_CLK_ENABLE();
  __HAL_RCC_GPIOD_CLK_ENABLE();

  /*Configure GPIO pin Output Level */
  HAL_GPIO_WritePin(GPIOC, LED3_Pin|PASS_Pin|FAIL_Pin|ADC_MUX_A_Pin
                          |ADC_MUX_B_Pin|PIN5EN_Pin|PIN2EN_Pin|Buffer_OE_Pin, GPIO_PIN_RESET);

  /*Configure GPIO pin Output Level */
  HAL_GPIO_WritePin(GPIOF, KP_R1_Pin|KP_R2_Pin|KP_R3_Pin|KP_R4_Pin, GPIO_PIN_RESET);

  /*Configure GPIO pin Output Level */
  HAL_GPIO_WritePin(GPIOB, LED1_Pin|LED2_Pin|DAC_CS3_Pin|DAC_CS2_Pin
                          |DAC_CS1_Pin|SOLAR_CH_EN_Pin, GPIO_PIN_RESET);

  /*Configure GPIO pin Output Level */
  HAL_GPIO_WritePin(GPIOF, MUX_WRodd1_Pin|MUX_WReven1_Pin, GPIO_PIN_SET);

  /*Configure GPIO pin Output Level */
  HAL_GPIO_WritePin(GPIOG, MUX_WRodd2_Pin|MUX_WReven2_Pin, GPIO_PIN_SET);

  /*Configure GPIO pin Output Level */
  HAL_GPIO_WritePin(GPIOE, MUX_WRodd3_Pin|MUX_WReven3_Pin|MUX_RS_Pin, GPIO_PIN_SET);

  /*Configure GPIO pin Output Level */
  HAL_GPIO_WritePin(GPIOE, MUX_A0_Pin|MUX_A1_Pin|MUX_EN_Pin, GPIO_PIN_RESET);

  /*Configure GPIO pin Output Level */
  HAL_GPIO_WritePin(GPIOD, ASYNC1_Pin|ASYNC2_Pin|TB_Reset_Pin|Radio_EN_Pin
                          |RS485_EN_Pin, GPIO_PIN_RESET);

  /*Configure GPIO pin Output Level */
  HAL_GPIO_WritePin(GPIOG, ASYNC3_Pin|ASYNC4_Pin|ASYNC5_Pin|ASYNC6_Pin
                          |ASYNC7_Pin|ASYNC8_Pin|ASYNC9_Pin, GPIO_PIN_RESET);

  /*Configure GPIO pin Output Level */
  HAL_GPIO_WritePin(RS485_4011EN_GPIO_Port, RS485_4011EN_Pin, GPIO_PIN_RESET);

  /*Configure GPIO pins : LED3_Pin PASS_Pin FAIL_Pin ADC_MUX_A_Pin
                           ADC_MUX_B_Pin PIN5EN_Pin PIN2EN_Pin Buffer_OE_Pin */
  GPIO_InitStruct.Pin = LED3_Pin|PASS_Pin|FAIL_Pin|ADC_MUX_A_Pin
                          |ADC_MUX_B_Pin|PIN5EN_Pin|PIN2EN_Pin|Buffer_OE_Pin;
  GPIO_InitStruct.Mode = GPIO_MODE_OUTPUT_PP;
  GPIO_InitStruct.Pull = GPIO_NOPULL;
  GPIO_InitStruct.Speed = GPIO_SPEED_FREQ_LOW;
  HAL_GPIO_Init(GPIOC, &GPIO_InitStruct);

  /*Configure GPIO pins : KP_R1_Pin KP_R2_Pin KP_R3_Pin KP_R4_Pin */
  GPIO_InitStruct.Pin = KP_R1_Pin|KP_R2_Pin|KP_R3_Pin|KP_R4_Pin;
  GPIO_InitStruct.Mode = GPIO_MODE_OUTPUT_PP;
  GPIO_InitStruct.Pull = GPIO_NOPULL;
  GPIO_InitStruct.Speed = GPIO_SPEED_FREQ_LOW;
  HAL_GPIO_Init(GPIOF, &GPIO_InitStruct);

  /*Configure GPIO pins : KP_C1_Pin KP_C2_Pin KP_C3_Pin */
  GPIO_InitStruct.Pin = KP_C1_Pin|KP_C2_Pin|KP_C3_Pin;
  GPIO_InitStruct.Mode = GPIO_MODE_INPUT;
  GPIO_InitStruct.Pull = GPIO_PULLUP;
  HAL_GPIO_Init(GPIOF, &GPIO_InitStruct);

  /*Configure GPIO pins : LED1_Pin DAC_CS3_Pin DAC_CS2_Pin DAC_CS1_Pin
                           SOLAR_CH_EN_Pin */
  GPIO_InitStruct.Pin = LED1_Pin|DAC_CS3_Pin|DAC_CS2_Pin|DAC_CS1_Pin
                          |SOLAR_CH_EN_Pin;
  GPIO_InitStruct.Mode = GPIO_MODE_OUTPUT_PP;
  GPIO_InitStruct.Pull = GPIO_NOPULL;
  GPIO_InitStruct.Speed = GPIO_SPEED_FREQ_LOW;
  HAL_GPIO_Init(GPIOB, &GPIO_InitStruct);

  /*Configure GPIO pin : LED2_Pin */
  GPIO_InitStruct.Pin = LED2_Pin;
  GPIO_InitStruct.Mode = GPIO_MODE_OUTPUT_PP;
  GPIO_InitStruct.Pull = GPIO_NOPULL;
  GPIO_InitStruct.Speed = GPIO_SPEED_FREQ_HIGH;
  HAL_GPIO_Init(LED2_GPIO_Port, &GPIO_InitStruct);

  /*Configure GPIO pins : MUX_WRodd1_Pin MUX_WReven1_Pin */
  GPIO_InitStruct.Pin = MUX_WRodd1_Pin|MUX_WReven1_Pin;
  GPIO_InitStruct.Mode = GPIO_MODE_OUTPUT_PP;
  GPIO_InitStruct.Pull = GPIO_PULLUP;
  GPIO_InitStruct.Speed = GPIO_SPEED_FREQ_LOW;
  HAL_GPIO_Init(GPIOF, &GPIO_InitStruct);

  /*Configure GPIO pins : MUX_WRodd2_Pin MUX_WReven2_Pin ASYNC5_Pin ASYNC6_Pin
                           ASYNC7_Pin ASYNC8_Pin ASYNC9_Pin */
  GPIO_InitStruct.Pin = MUX_WRodd2_Pin|MUX_WReven2_Pin|ASYNC5_Pin|ASYNC6_Pin
                          |ASYNC7_Pin|ASYNC8_Pin|ASYNC9_Pin;
  GPIO_InitStruct.Mode = GPIO_MODE_OUTPUT_PP;
  GPIO_InitStruct.Pull = GPIO_NOPULL;
  GPIO_InitStruct.Speed = GPIO_SPEED_FREQ_LOW;
  HAL_GPIO_Init(GPIOG, &GPIO_InitStruct);

  /*Configure GPIO pins : MUX_WRodd3_Pin MUX_WReven3_Pin MUX_A0_Pin MUX_A1_Pin
                           MUX_RS_Pin MUX_EN_Pin */
  GPIO_InitStruct.Pin = MUX_WRodd3_Pin|MUX_WReven3_Pin|MUX_A0_Pin|MUX_A1_Pin
                          |MUX_RS_Pin|MUX_EN_Pin;
  GPIO_InitStruct.Mode = GPIO_MODE_OUTPUT_PP;
  GPIO_InitStruct.Pull = GPIO_NOPULL;
  GPIO_InitStruct.Speed = GPIO_SPEED_FREQ_LOW;
  HAL_GPIO_Init(GPIOE, &GPIO_InitStruct);

  /*Configure GPIO pins : ASYNC1_Pin ASYNC2_Pin */
  GPIO_InitStruct.Pin = ASYNC1_Pin|ASYNC2_Pin;
  GPIO_InitStruct.Mode = GPIO_MODE_OUTPUT_PP;
  GPIO_InitStruct.Pull = GPIO_NOPULL;
  GPIO_InitStruct.Speed = GPIO_SPEED_FREQ_VERY_HIGH;
  HAL_GPIO_Init(GPIOD, &GPIO_InitStruct);

  /*Configure GPIO pins : ASYNC3_Pin ASYNC4_Pin */
  GPIO_InitStruct.Pin = ASYNC3_Pin|ASYNC4_Pin;
  GPIO_InitStruct.Mode = GPIO_MODE_OUTPUT_PP;
  GPIO_InitStruct.Pull = GPIO_NOPULL;
  GPIO_InitStruct.Speed = GPIO_SPEED_FREQ_VERY_HIGH;
  HAL_GPIO_Init(GPIOG, &GPIO_InitStruct);

  /*Configure GPIO pin : RS485_4011EN_Pin */
  GPIO_InitStruct.Pin = RS485_4011EN_Pin;
  GPIO_InitStruct.Mode = GPIO_MODE_OUTPUT_PP;
  GPIO_InitStruct.Pull = GPIO_NOPULL;
  GPIO_InitStruct.Speed = GPIO_SPEED_FREQ_LOW;
  HAL_GPIO_Init(RS485_4011EN_GPIO_Port, &GPIO_InitStruct);

  /*Configure GPIO pins : TB_Reset_Pin Radio_EN_Pin RS485_EN_Pin */
  GPIO_InitStruct.Pin = TB_Reset_Pin|Radio_EN_Pin|RS485_EN_Pin;
  GPIO_InitStruct.Mode = GPIO_MODE_OUTPUT_PP;
  GPIO_InitStruct.Pull = GPIO_NOPULL;
  GPIO_InitStruct.Speed = GPIO_SPEED_FREQ_LOW;
  HAL_GPIO_Init(GPIOD, &GPIO_InitStruct);

  /*Configure GPIO pin : Loom_Sel_Pin */
  GPIO_InitStruct.Pin = Loom_Sel_Pin;
  GPIO_InitStruct.Mode = GPIO_MODE_INPUT;
  GPIO_InitStruct.Pull = GPIO_PULLUP;
  HAL_GPIO_Init(Loom_Sel_GPIO_Port, &GPIO_InitStruct);

  /*Configure GPIO pin : SD_Det_Pin */
  GPIO_InitStruct.Pin = SD_Det_Pin;
  GPIO_InitStruct.Mode = GPIO_MODE_INPUT;
  GPIO_InitStruct.Pull = GPIO_NOPULL;
  HAL_GPIO_Init(SD_Det_GPIO_Port, &GPIO_InitStruct);

}

void Error_Handler(void)
{
  /* USER CODE BEGIN Error_Handler_Debug */
	/* User can add his own implementation to report the HAL error return state */
	__disable_irq();
	HAL_GPIO_WritePin(LED2_GPIO_Port, LED2_Pin, GPIO_PIN_SET);
	while (1) {
		HAL_GPIO_WritePin(LED1_GPIO_Port, LED1_Pin, GPIO_PIN_RESET);
		HAL_Delay(500);
		HAL_GPIO_WritePin(LED1_GPIO_Port, LED1_Pin, GPIO_PIN_SET);
		HAL_Delay(500);
		HAL_GPIO_WritePin(LED1_GPIO_Port, LED1_Pin, GPIO_PIN_SET);
		HAL_Delay(20);
		HAL_GPIO_WritePin(LED1_GPIO_Port, LED1_Pin, GPIO_PIN_RESET);
		HAL_Delay(20);
		HAL_GPIO_WritePin(LED1_GPIO_Port, LED1_Pin, GPIO_PIN_SET);
		HAL_Delay(20);
		HAL_GPIO_WritePin(LED1_GPIO_Port, LED1_Pin, GPIO_PIN_RESET);
		HAL_Delay(20);
		HAL_GPIO_WritePin(LED1_GPIO_Port, LED1_Pin, GPIO_PIN_SET);
		HAL_Delay(20);
		HAL_GPIO_WritePin(LED1_GPIO_Port, LED1_Pin, GPIO_PIN_RESET);
		HAL_Delay(20);
	}
  /* USER CODE END Error_Handler_Debug */
}

/************************ (C) COPYRIGHT STMicroelectronics *****END OF FILE****/
